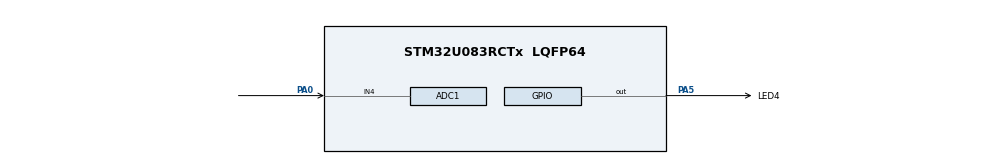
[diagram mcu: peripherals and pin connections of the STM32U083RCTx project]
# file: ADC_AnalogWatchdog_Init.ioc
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ADC1.AWD1HighThreshold=ADC_AWD_THRESHOLD_HIGH
ADC1.AWD1ITMode=ENABLE
ADC1.AWD1LowThreshold=ADC_AWD_THRESHOLD_LOW
ADC1.Channel-1\#ChannelRegularConversion=ADC_CHANNEL_4
ADC1.ClockPrescaler=ADC_CLOCK_SYNC_PCLK_DIV4
ADC1.ContinuousConvMode=ENABLE
ADC1.EnableAnalogWatchDog1=true
ADC1.NbrOfConversionFlag=1
ADC1.Overrun=ADC_OVR_DATA_OVERWRITTEN
ADC1.Rank-1\#ChannelRegularConversion=1
ADC1.RankArg-1\#ChannelRegularConversion=ADC_REGULAR_RANK_1
ADC1.SamplingTime-1\#ChannelRegularConversion=ADC_SAMPLINGTIME_COMMON_1
ADC1.SamplingTimeCommon1=ADC_SAMPLETIME_160CYCLES_5
ADC1.SamplingTimeCommon2=ADC_SAMPLETIME_160CYCLES_5
ADC1.SelectedChannel=ADC_CHANNEL_4
ADC1.WatchdogMode=ADC_ANALOGWATCHDOG_ALL_REG
ADC1.master=1
Mcu.Family=STM32U0
Mcu.Name=STM32U083RCTx
Mcu.Package=LQFP64
NVIC.ADC_COMP1_2_IRQn=true\:0\:0\:false\:false\:true\:true\:true\:true
NVIC.PriorityGroup=NVIC_PRIORITYGROUP_2
PA0.Mode=IN4
PA0.Signal=ADC1_IN4
PA5.GPIO_Label=LED4
PA5.Signal=GPIO_Output
ProjectManager.HeapSize=0x200
ProjectManager.StackSize=0x400
ProjectManager.TargetToolchain=EWARM V8
RCC.ADCFreq_Value=48000000
RCC.AHBFreq_Value=48000000
RCC.CortexFreq_Value=48000000
RCC.HCLKFreq_Value=48000000
RCC.HSE_VALUE=4000000
RCC.HSI48_VALUE=48000000
RCC.HSI_VALUE=16000000
RCC.LSE_VALUE=32768
RCC.MSIClockRangeVal=RCC_MSIRANGE_11
RCC.MSI_VALUE=48000000
RCC.SYSCLKFreq_VALUE=48000000
RCC.SYSCLKSource=RCC_SYSCLKSOURCE_MSI
RCC.USBFreq_Value=48000000
RCC.VCOOutputFreq_Value=64000000
VP_PWR_VS_SECSignals.Mode=Security/Privilege
board=custom

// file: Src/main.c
/* USER CODE BEGIN Header */
/**
  ******************************************************************************
  * @file    Examples_LL/ADC/ADC_AnalogWatchdog_Init/Src/main.c
  * @author  MCD Application Team
  * @brief   This example describes how to use a ADC peripheral
  *          with ADC analog watchdog to monitor a channel and detect
  *          when the corresponding conversion data is out of window thresholds.
  *          This example is based on the STM32U0xx ADC LL API;
  *          Peripheral initialization done using LL unitary services functions.
  ******************************************************************************
  * @attention
  *
  * Copyright (c) 2023 STMicroelectronics.
  * All rights reserved.
  *
  * This software is licensed under terms that can be found in the LICENSE file
  * in the root directory of this software component.
  * If no LICENSE file comes with this software, it is provided AS-IS.
  *
  ******************************************************************************
  */
/* USER CODE END Header */
#include "main.h"

/* USER CODE BEGIN PD */

/* Definitions of ADC hardware constraints delays */
/* Note: Only ADC IP HW delays are defined in ADC LL driver driver,           */
/*       not timeout values:                                                  */
/*       Timeout values for ADC operations are dependent to device clock      */
/*       configuration (system clock versus ADC clock),                       */
/*       and therefore must be defined in user application.                   */
/*       Refer to @ref ADC_LL_EC_HW_DELAYS for description of ADC timeout     */
/*       values definition.                                                   */

  /* Timeout values for ADC operations. */
  /* (calibration, enable settling time, disable settling time, ...)          */
  /* Values defined to be higher than worst cases: low clock frequency,       */
  /* maximum prescalers.                                                      */
  /* Note: ADC channel configuration ready (ADC_CHANNEL_CONF_RDY_TIMEOUT_MS)  */
  /*       is added in CubeMx code section.                                   */
  /* Unit: ms                                                                 */
  #define ADC_CALIBRATION_TIMEOUT_MS       (   1UL)
  #define ADC_ENABLE_TIMEOUT_MS            (   1UL)
  #define ADC_DISABLE_TIMEOUT_MS           (   1UL)
  #define ADC_STOP_CONVERSION_TIMEOUT_MS   (   1UL)
  #define ADC_CONVERSION_TIMEOUT_MS        (4000UL)

  /* Delay between ADC end of calibration and ADC enable.                     */
  /* Delay estimation in CPU cycles: Case of ADC enable done                  */
  /* immediately after ADC calibration, ADC clock setting slow                */
  /* (LL_ADC_CLOCK_ASYNC_DIV32). Use a higher delay if ratio                  */
  /* (CPU clock / ADC clock) is above 32.                                     */
  #define ADC_DELAY_CALIB_ENABLE_CPU_CYCLES  (LL_ADC_DELAY_CALIB_ENABLE_ADC_CYCLES * 32)

/* Definitions of environment analog values */
  /* Value of analog reference voltage (Vref+), connected to analog voltage   */
  /* supply Vdda (unit: mV).                                                  */
  #define VDDA_APPLI                       (3300UL)

/* Definitions of data related to this example */
  /* Definition of ADCx analog watchdog window thresholds */
  #define ADC_AWD_THRESHOLD_HIGH           (__LL_ADC_DIGITAL_SCALE(LL_ADC_RESOLUTION_12B) / 2) /* Value of ADC analog watchdog threshold high */
  #define ADC_AWD_THRESHOLD_LOW            (   0UL) /* Value of ADC analog watchdog threshold low */

  /* Init variable out of expected ADC conversion data range */
  #define VAR_CONVERTED_DATA_INIT_VALUE    (__LL_ADC_DIGITAL_SCALE(LL_ADC_RESOLUTION_12B) + 1)

  #define ADC_AWD_REARM_DELAY_MS           (5000UL) /* ADC analog watchdog rearm delay (unit: ms) */

/* USER CODE END PD */

/* USER CODE BEGIN PV */

/* Variables for ADC conversion data */
__IO uint16_t uhADCxConvertedData = VAR_CONVERTED_DATA_INIT_VALUE; /* ADC group regular conversion data */

/* Variable to report status of ADC analog watchdog 1:                        */
/*  0: ADC conversion data into AWD window                                    */
/*  1: ADC conversion data out of AWD window                                  */
__IO uint8_t ubAnalogWatchdog1Status = 0U; /* Variable set into analog watchdog 1 interruption callback */

uint32_t led_toggle_period_ms = LED_BLINK_SLOW; /* LED toggle period (unit: ms) */
uint32_t adc_awd_rearm_delay_iterations_count; /* ADC analog watchdog rearm delay iterations count */

/* USER CODE END PV */

void SystemClock_Config(void);
static void MX_GPIO_Init(void);
static void MX_ADC1_Init(void);
/* USER CODE BEGIN PFP */

void ADC_Activate(void);
void ADC_AnalogWatchdog_Rearm(void);
void LED_On(void);
void LED_Off(void);
void LED_Toggle(void);

/* USER CODE END PFP */

int main(void)
{

  /* MCU Configuration--------------------------------------------------------*/

  /* Reset of all peripherals, Initializes the Flash interface and the Systick. */
  LL_APB1_GRP1_EnableClock(LL_APB1_GRP1_PERIPH_PWR);
  LL_APB1_GRP2_EnableClock(LL_APB1_GRP2_PERIPH_SYSCFG);

  /* System interrupt init*/
  NVIC_SetPriorityGrouping(NVIC_PRIORITYGROUP_2);

  /* SysTick_IRQn interrupt configuration */
  NVIC_SetPriority(SysTick_IRQn, NVIC_EncodePriority(NVIC_GetPriorityGrouping(),3, 0));

  /* Configure the system clock */
  SystemClock_Config();

  /* Initialize all configured peripherals */
  MX_GPIO_Init();
  MX_ADC1_Init();
  /* USER CODE BEGIN 2 */

  /* Activate ADC */
  /* Perform ADC activation procedure to make it ready to convert. */
  ADC_Activate();

  /* Start ADC group regular conversion */
  /* Note: Hardware constraint (refer to description of the functions         */
  /*       below):                                                            */
  /*       On this STM32 series, setting of this feature is conditioned to    */
  /*       ADC state:                                                         */
  /*       ADC must be enabled without conversion on going on group regular,  */
  /*       without ADC disable command on going.                              */
  /* Note: In this example, all these checks are not necessary but are        */
  /*       implemented anyway to show the best practice usages                */
  /*       corresponding to reference manual procedure.                       */
  /*       Software can be optimized by removing some of these checks, if     */
  /*       they are not relevant considering previous settings and actions    */
  /*       in user application.                                               */
  if ((LL_ADC_IsEnabled(ADC1) == 1)               &&
      (LL_ADC_IsDisableOngoing(ADC1) == 0)        &&
      (LL_ADC_REG_IsConversionOngoing(ADC1) == 0)   )
  {
    LL_ADC_REG_StartConversion(ADC1);
  }
  else
  {
    /* Error: ADC conversion start could not be performed */
    Error_Handler();
  }

  /* USER CODE END 2 */

  /* Infinite loop */
  /* USER CODE BEGIN WHILE */
  while (1)
  {
    /* Process analog watchdog out of window event */
    if(ubAnalogWatchdog1Status == 1)
    {
      /* Wait for ADC analog watchdog rearm */
      adc_awd_rearm_delay_iterations_count--;
      if(adc_awd_rearm_delay_iterations_count == 0)
      {
        led_toggle_period_ms = LED_BLINK_SLOW;

        /* Reset status variable of ADC analog watchdog 1 */
        ubAnalogWatchdog1Status = 0;

        /* Rearm ADC analog watchdog to make it ready for another trig */
        ADC_AnalogWatchdog_Rearm();
      }
    }

    LED_Toggle();
    LL_mDelay(led_toggle_period_ms);

    /* Note: LED state depending on ADC analog watchdog 1 status              */
    /*       variable "ubAnalogWatchdog1Status"                               */
    /*       is set into ADC analog watchdog 1 IRQ handler,                   */
    /*       refer to function "AdcAnalogWatchdog1_Callback()".               */

    /* USER CODE END WHILE */

  }
}

void SystemClock_Config(void)
{
  LL_FLASH_SetLatency(LL_FLASH_LATENCY_1);
  while(LL_FLASH_GetLatency() != LL_FLASH_LATENCY_1)
  {
  }

  LL_PWR_SetRegulVoltageScaling(LL_PWR_REGU_VOLTAGE_SCALE1);
  while (LL_PWR_IsActiveFlag_VOS() != 0)
  {
  }
  LL_RCC_MSI_Enable();

   /* Wait till MSI is ready */
  while(LL_RCC_MSI_IsReady() != 1)
  {
  }

  LL_RCC_MSI_EnableRangeSelection();
  LL_RCC_MSI_SetRange(LL_RCC_MSIRANGE_11);
  LL_RCC_SetSysClkSource(LL_RCC_SYS_CLKSOURCE_MSI);

   /* Wait till System clock is ready */
  while(LL_RCC_GetSysClkSource() != LL_RCC_SYS_CLKSOURCE_STATUS_MSI)
  {
  }

  LL_RCC_SetAHBPrescaler(LL_RCC_SYSCLK_DIV_1);
  LL_RCC_SetAPB1Prescaler(LL_RCC_APB1_DIV_1);

  LL_Init1msTick(48000000);

  LL_SetSystemCoreClock(48000000);
}

static void MX_ADC1_Init(void)
{

  LL_ADC_InitTypeDef ADC_InitStruct = {0};
  LL_ADC_REG_InitTypeDef ADC_REG_InitStruct = {0};

  LL_GPIO_InitTypeDef GPIO_InitStruct = {0};

  LL_RCC_SetADCClockSource(LL_RCC_ADC_CLKSOURCE_SYSCLK);

  /* Peripheral clock enable */
  LL_APB1_GRP2_EnableClock(LL_APB1_GRP2_PERIPH_ADC);

  LL_IOP_GRP1_EnableClock(LL_IOP_GRP1_PERIPH_GPIOA);
  /**ADC1 GPIO Configuration
  PA0   ------> ADC1_IN4
  */
  GPIO_InitStruct.Pin = LL_GPIO_PIN_0;
  GPIO_InitStruct.Mode = LL_GPIO_MODE_ANALOG;
  GPIO_InitStruct.Pull = LL_GPIO_PULL_NO;
  LL_GPIO_Init(GPIOA, &GPIO_InitStruct);

  /* ADC1 interrupt Init */
  NVIC_SetPriority(ADC_COMP1_2_IRQn, NVIC_EncodePriority(NVIC_GetPriorityGrouping(),0, 0));
  NVIC_EnableIRQ(ADC_COMP1_2_IRQn);

  /** Configure the global features of the ADC (Clock, Resolution, Data Alignment and number of conversion)
  */

   #define ADC_CHANNEL_CONF_RDY_TIMEOUT_MS ( 1U)
   #if (USE_TIMEOUT == 1)
   uint32_t Timeout ; /* Variable used for Timeout management */
   #endif /* USE_TIMEOUT */

  ADC_InitStruct.Clock = LL_ADC_CLOCK_SYNC_PCLK_DIV4;
  ADC_InitStruct.Resolution = LL_ADC_RESOLUTION_12B;
  ADC_InitStruct.DataAlignment = LL_ADC_DATA_ALIGN_RIGHT;
  ADC_InitStruct.LowPowerMode = LL_ADC_LP_MODE_NONE;
  LL_ADC_Init(ADC1, &ADC_InitStruct);
  LL_ADC_REG_SetSequencerConfigurable(ADC1, LL_ADC_REG_SEQ_CONFIGURABLE);

   /* Poll for ADC channel configuration ready */
   #if (USE_TIMEOUT == 1)
   Timeout = ADC_CHANNEL_CONF_RDY_TIMEOUT_MS;
   #endif /* USE_TIMEOUT */
   while (LL_ADC_IsActiveFlag_CCRDY(ADC1) == 0)
     {
   #if (USE_TIMEOUT == 1)
   /* Check Systick counter flag to decrement the time-out value */
   if (LL_SYSTICK_IsActiveCounterFlag())
     {
   if(Timeout-- == 0)
         {
   Error_Handler();
         }
     }
   #endif /* USE_TIMEOUT */
     }
   /* Clear flag ADC channel configuration ready */
   LL_ADC_ClearFlag_CCRDY(ADC1);
  ADC_REG_InitStruct.TriggerSource = LL_ADC_REG_TRIG_SOFTWARE;
  ADC_REG_InitStruct.SequencerLength = LL_ADC_REG_SEQ_SCAN_DISABLE;
  ADC_REG_InitStruct.ContinuousMode = LL_ADC_REG_CONV_CONTINUOUS;
  ADC_REG_InitStruct.DMATransfer = LL_ADC_REG_DMA_TRANSFER_NONE;
  ADC_REG_InitStruct.Overrun = LL_ADC_REG_OVR_DATA_OVERWRITTEN;
  LL_ADC_REG_Init(ADC1, &ADC_REG_InitStruct);
  LL_ADC_SetOverSamplingScope(ADC1, LL_ADC_OVS_DISABLE);
  LL_ADC_SetTriggerFrequencyMode(ADC1, LL_ADC_TRIGGER_FREQ_HIGH);
  LL_ADC_SetSamplingTimeCommonChannels(ADC1, LL_ADC_SAMPLINGTIME_COMMON_1, LL_ADC_SAMPLINGTIME_160CYCLES_5);
  LL_ADC_SetSamplingTimeCommonChannels(ADC1, LL_ADC_SAMPLINGTIME_COMMON_2, LL_ADC_SAMPLINGTIME_160CYCLES_5);
  LL_ADC_DisableIT_EOC(ADC1);
  LL_ADC_DisableIT_EOS(ADC1);

   /* Enable ADC internal voltage regulator */
   LL_ADC_EnableInternalRegulator(ADC1);
   /* Delay for ADC internal voltage regulator stabilization. */
   /* Compute number of CPU cycles to wait for, from delay in us. */
   /* Note: Variable divided by 2 to compensate partially */
   /* CPU processing cycles (depends on compilation optimization). */
   /* Note: If system core clock frequency is below 200kHz, wait time */
   /* is only a few CPU processing cycles. */
   uint32_t wait_loop_index;
   wait_loop_index = ((LL_ADC_DELAY_INTERNAL_REGUL_STAB_US * (SystemCoreClock / (100000 * 2))) / 10);
   while(wait_loop_index != 0)
     {
   wait_loop_index--;
     }

  /** Configure Analog WatchDog 1
  */
  LL_ADC_SetAnalogWDMonitChannels(ADC1, LL_ADC_AWD1, LL_ADC_AWD_ALL_CHANNELS_REG);
  LL_ADC_ConfigAnalogWDThresholds(ADC1, LL_ADC_AWD1, ADC_AWD_THRESHOLD_HIGH, ADC_AWD_THRESHOLD_LOW);
  LL_ADC_EnableIT_AWD1(ADC1);

  /** Configure Regular Channel
  */
  LL_ADC_REG_SetSequencerRanks(ADC1, LL_ADC_REG_RANK_1, LL_ADC_CHANNEL_4);

   /* Poll for ADC channel configuration ready */
   #if (USE_TIMEOUT == 1)
   Timeout = ADC_CHANNEL_CONF_RDY_TIMEOUT_MS;
   #endif /* USE_TIMEOUT */
   while (LL_ADC_IsActiveFlag_CCRDY(ADC1) == 0)
     {
   #if (USE_TIMEOUT == 1)
   /* Check Systick counter flag to decrement the time-out value */
   if (LL_SYSTICK_IsActiveCounterFlag())
     {
   if(Timeout-- == 0)
         {
   Error_Handler();
         }
     }
   #endif /* USE_TIMEOUT */
     }
   /* Clear flag ADC channel configuration ready */
   LL_ADC_ClearFlag_CCRDY(ADC1);
  LL_ADC_SetChannelSamplingTime(ADC1, LL_ADC_CHANNEL_4, LL_ADC_SAMPLINGTIME_COMMON_1);

}

static void MX_GPIO_Init(void)
{
  LL_GPIO_InitTypeDef GPIO_InitStruct = {0};

  /* GPIO Ports Clock Enable */
  LL_IOP_GRP1_EnableClock(LL_IOP_GRP1_PERIPH_GPIOA);

  /**/
  LL_GPIO_ResetOutputPin(LED4_GPIO_Port, LED4_Pin);

  /**/
  GPIO_InitStruct.Pin = LED4_Pin;
  GPIO_InitStruct.Mode = LL_GPIO_MODE_OUTPUT;
  GPIO_InitStruct.Speed = LL_GPIO_SPEED_FREQ_LOW;
  GPIO_InitStruct.OutputType = LL_GPIO_OUTPUT_PUSHPULL;
  GPIO_InitStruct.Pull = LL_GPIO_PULL_NO;
  LL_GPIO_Init(LED4_GPIO_Port, &GPIO_InitStruct);

}

/* USER CODE BEGIN 4 */

/**
  * @brief  Perform ADC activation procedure to make it ready to convert
  *         (ADC instance: ADC1).
  * @param  None
  * @retval None
  */
void ADC_Activate(void)
{
  __IO uint32_t wait_loop_index = 0U;
  __IO uint32_t backup_setting_adc_dma_transfer = 0U;
  #if (USE_TIMEOUT == 1)
  uint32_t Timeout = 0U; /* Variable used for timeout management */
  #endif /* USE_TIMEOUT */

  /*## Operation on ADC hierarchical scope: ADC instance #####################*/

  /* Note: Hardware constraint (refer to description of the functions         */
  /*       below):                                                            */
  /*       On this STM32 series, setting of these features is conditioned to  */
  /*       ADC state:                                                         */
  /*       ADC must be disabled.                                              */
  /* Note: In this example, all these checks are not necessary but are        */
  /*       implemented anyway to show the best practice usages                */
  /*       corresponding to reference manual procedure.                       */
  /*       Software can be optimized by removing some of these checks, if     */
  /*       they are not relevant considering previous settings and actions    */
  /*       in user application.                                               */
  if (LL_ADC_IsEnabled(ADC1) == 0)
  {
    /* Enable ADC internal voltage regulator */
    LL_ADC_EnableInternalRegulator(ADC1);

    /* Delay for ADC internal voltage regulator stabilization.                */
    /* Compute number of CPU cycles to wait for, from delay in us.            */
    /* Note: Variable divided by 2 to compensate partially                    */
    /*       CPU processing cycles (depends on compilation optimization).     */
    /* Note: If system core clock frequency is below 200kHz, wait time        */
    /*       is only a few CPU processing cycles.                             */
    wait_loop_index = ((LL_ADC_DELAY_INTERNAL_REGUL_STAB_US * (SystemCoreClock / (100000 * 2))) / 10);
    while(wait_loop_index != 0)
    {
      wait_loop_index--;
    }

    /* Disable ADC DMA transfer request during calibration */
    /* Note: Specificity of this STM32 series: Calibration factor is           */
    /*       available in data register and also transferred by DMA.           */
    /*       To not insert ADC calibration factor among ADC conversion data   */
    /*       in DMA destination address, DMA transfer must be disabled during */
    /*       calibration.                                                     */
    backup_setting_adc_dma_transfer = LL_ADC_REG_GetDMATransfer(ADC1);
    LL_ADC_REG_SetDMATransfer(ADC1, LL_ADC_REG_DMA_TRANSFER_NONE);

    /* Run ADC self calibration */
    LL_ADC_StartCalibration(ADC1);

    /* Poll for ADC effectively calibrated */
    #if (USE_TIMEOUT == 1)
    Timeout = ADC_CALIBRATION_TIMEOUT_MS;
    #endif /* USE_TIMEOUT */

    while (LL_ADC_IsCalibrationOnGoing(ADC1) != 0)
    {
    #if (USE_TIMEOUT == 1)
      /* Check Systick counter flag to decrement the time-out value */
      if (LL_SYSTICK_IsActiveCounterFlag())
      {
        if(Timeout-- == 0)
        {
          /* Error: Time-out */
          Error_Handler();
        }
      }
    #endif /* USE_TIMEOUT */
    }

    /* Restore ADC DMA transfer request after calibration */
    LL_ADC_REG_SetDMATransfer(ADC1, backup_setting_adc_dma_transfer);

    /* Delay between ADC end of calibration and ADC enable.                   */
    /* Note: Variable divided by 2 to compensate partially                    */
    /*       CPU processing cycles (depends on compilation optimization).     */
    wait_loop_index = (ADC_DELAY_CALIB_ENABLE_CPU_CYCLES >> 1);
    while(wait_loop_index != 0)
    {
      wait_loop_index--;
    }

    /* Enable ADC */
    LL_ADC_Enable(ADC1);

    /* Poll for ADC ready to convert */
    #if (USE_TIMEOUT == 1)
    Timeout = ADC_ENABLE_TIMEOUT_MS;
    #endif /* USE_TIMEOUT */

    while (LL_ADC_IsActiveFlag_ADRDY(ADC1) == 0)
    {
    #if (USE_TIMEOUT == 1)
      /* Check Systick counter flag to decrement the time-out value */
      if (LL_SYSTICK_IsActiveCounterFlag())
      {
        if(Timeout-- == 0)
        {
          /* Error: Time-out */
          Error_Handler();
        }
      }
    #endif /* USE_TIMEOUT */
    }

    /* Note: ADC flag ADRDY is not cleared here to be able to check ADC       */
    /*       status afterwards.                                               */
    /*       This flag should be cleared at ADC Deactivation, before a new    */
    /*       ADC activation, using function "LL_ADC_ClearFlag_ADRDY()".       */
  }

  /*## Operation on ADC hierarchical scope: ADC group regular ################*/
  /* Note: No operation on ADC group regular performed here.                  */
  /*       ADC group regular conversions to be performed after this function  */
  /*       using function:                                                    */
  /*       "LL_ADC_REG_StartConversion();"                                    */

  /*## Operation on ADC hierarchical scope: ADC group injected ###############*/
  /* Note: No operation on ADC group injected performed here.                 */
  /*       ADC group injected conversions to be performed after this function */
  /*       using function:                                                    */
  /*       "LL_ADC_INJ_StartConversion();"                                    */

}

/**
  * @brief  Rearm ADC analog watchdog to make it ready another trig
  *         (ADC instance: ADC1, analog watchdog instance: AWD1).
  * @param  None
  * @retval None
  */
void ADC_AnalogWatchdog_Rearm(void)
{
  /* Clear flag ADC analog watchdog 1 */
  LL_ADC_ClearFlag_AWD1(ADC1);

  /* Enable ADC analog watchdog 1 interruption */
  LL_ADC_EnableIT_AWD1(ADC1);
}

/**
  * @brief  Turn-on LED4.
  * @param  None
  * @retval None
  */
void LED_On(void)
{
  /* Turn LED on */
  LL_GPIO_SetOutputPin(LED4_GPIO_Port, LED4_Pin);
}

/**
  * @brief  Turn-off LED4.
  * @param  None
  * @retval None
  */
void LED_Off(void)
{
  /* Turn LED off */
  LL_GPIO_ResetOutputPin(LED4_GPIO_Port, LED4_Pin);
}

/**
  * @brief  Toggle LED4.
  * @param  None
  * @retval None
  */
void LED_Toggle(void)
{
  /* Turn LED off */
  LL_GPIO_TogglePin(LED4_GPIO_Port, LED4_Pin);
}

/******************************************************************************/
/*   USER IRQ HANDLER TREATMENT                                               */
/******************************************************************************/

/**
  * @brief  ADC analog watchdog 1 interruption callback
  * @note   This function is executed when the ADC conversion data is
  *         out of analog watchdog 1 window thresholds.
  * @retval None
  */
void AdcAnalogWatchdog1_Callback()
{
  /* Disable ADC analog watchdog 1 interruption */
  /* Note: ADC analog watchdog 1 interruption rearmed afterwards after
           event processing completion */
  LL_ADC_DisableIT_AWD1(ADC1);

  /* Retrieve ADC conversion data */
  /* Note: data scale corresponds to ADC resolution */
  uhADCxConvertedData = LL_ADC_REG_ReadConversionData32(ADC1);

  /* Update status variable of ADC analog watchdog 1 */
  ubAnalogWatchdog1Status = 1;

  /* Change LED toggle frequency depending on voltage below or above
     analog watchdog window */
  if (uhADCxConvertedData > ADC_AWD_THRESHOLD_HIGH)
  {
    led_toggle_period_ms = LED_BLINK_VERY_FAST;
  }
  else if (ADC_AWD_THRESHOLD_LOW < uhADCxConvertedData)
  {
    led_toggle_period_ms = LED_BLINK_SLOW;
  }
  else /* (uhADCxConvertedData < ADC_AWD_THRESHOLD_LOW) */
  {
    led_toggle_period_ms = LED_BLINK_FAST;
  }

  /* Set ADC analog watchdog rearm delay iterations count */
  adc_awd_rearm_delay_iterations_count = (ADC_AWD_REARM_DELAY_MS / led_toggle_period_ms);
}

/* USER CODE END 4 */

void Error_Handler(void)
{
  /* USER CODE BEGIN Error_Handler_Debug */
  /* User can add his own implementation to report the HAL error return state */

  /* Turn on LED and remain in infinite loop */
  while (1)
  {
    LED_On();
  }
  /* USER CODE END Error_Handler_Debug */
}
